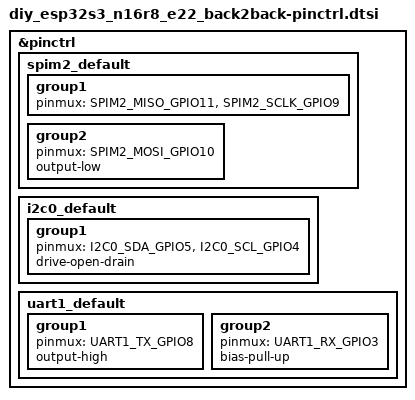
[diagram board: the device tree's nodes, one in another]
#include <zephyr/dt-bindings/pinctrl/esp-pinctrl-common.h>
#include <zephyr/dt-bindings/pinctrl/esp32s3-pinctrl.h>
#include <zephyr/dt-bindings/pinctrl/esp32s3-gpio-sigmap.h>

&pinctrl {
	spim2_default: spim2_default {
		group1 {
			pinmux = <SPIM2_MISO_GPIO11>,
				 <SPIM2_SCLK_GPIO9>;
		};
		group2 {
			pinmux = <SPIM2_MOSI_GPIO10>;
			output-low;
		};
	};

	i2c0_default: i2c0_default {
		group1 {
			pinmux = <I2C0_SDA_GPIO5>,
				 <I2C0_SCL_GPIO4>;
			drive-open-drain;
		};
	};

	uart1_default: uart1_default {
		group1 {
			pinmux = <UART1_TX_GPIO8>;
			output-high;
		};
		group2 {
			pinmux = <UART1_RX_GPIO3>;
			bias-pull-up;
		};
	};
};
